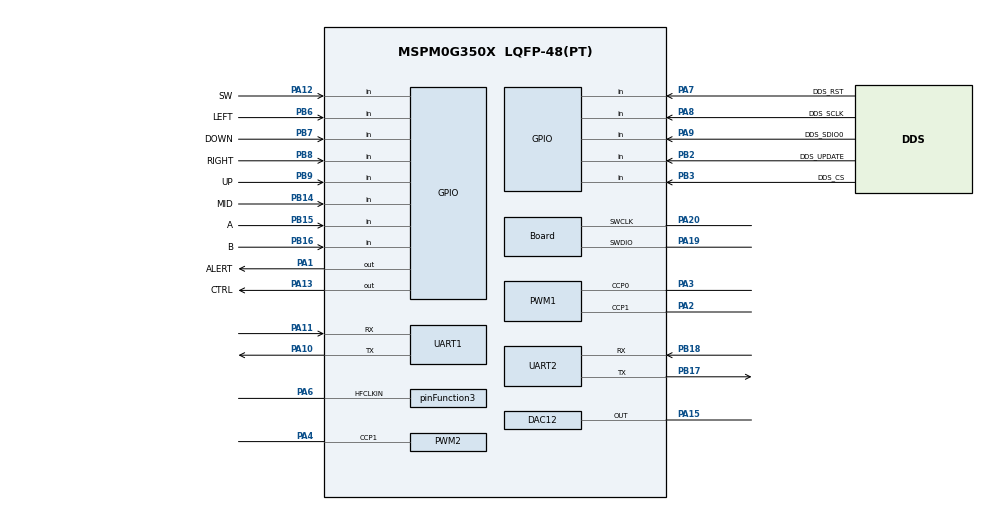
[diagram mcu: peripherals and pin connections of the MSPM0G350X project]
/**
 * @cliArgs --device "MSPM0G350X" --package "LQFP-48(PT)" --part "Default" --product "mspm0_sdk@2.10.00.04"
 * @versions {"tool":"1.19.0+3426"}
 */

/**
 * Import the modules used in this configuration.
 */
const ADC12         = scripting.addModule("/ti/driverlib/ADC12", {}, false);
const ADC121        = ADC12.addInstance();
const ADC122        = ADC12.addInstance();
const DAC12         = scripting.addModule("/ti/driverlib/DAC12");
const GPIO          = scripting.addModule("/ti/driverlib/GPIO", {}, false);
const GPIO1         = GPIO.addInstance();
const GPIO2         = GPIO.addInstance();
const GPIO3         = GPIO.addInstance();
const GPIO4         = GPIO.addInstance();
const GPIO5         = GPIO.addInstance();
const DMA           = scripting.addModule("/ti/driverlib/DMA");
const MATHACL       = scripting.addModule("/ti/driverlib/MATHACL");
const PWM           = scripting.addModule("/ti/driverlib/PWM", {}, false);
const PWM1          = PWM.addInstance();
const PWM2          = PWM.addInstance();
const SYSCTL        = scripting.addModule("/ti/driverlib/SYSCTL");
const SYSTICK       = scripting.addModule("/ti/driverlib/SYSTICK");
const TIMER         = scripting.addModule("/ti/driverlib/TIMER", {}, false);
const TIMER1        = TIMER.addInstance();
const UART          = scripting.addModule("/ti/driverlib/UART", {}, false);
const UART1         = UART.addInstance();
const UART2         = UART.addInstance();
const ProjectConfig = scripting.addModule("/ti/project_config/ProjectConfig");

/**
 * Write custom configuration values to the imported modules.
 */
const divider9       = system.clockTree["UDIV"];
divider9.divideValue = 2;

const dacClockGate    = system.clockTree["MFPCLKGATE"];
dacClockGate.enable   = true;

const multiplier2         = system.clockTree["PLL_QDIV"];
multiplier2.multiplyValue = 4;

const mux2       = system.clockTree["CANCLKMUX"];
mux2.inputSelect = "CANCLKMUX_PLLCLK1_OUT";

const mux8       = system.clockTree["HSCLKMUX"];
mux8.inputSelect = "HSCLKMUX_SYSPLL0";

const mux12       = system.clockTree["SYSPLLMUX"];
mux12.inputSelect = "zSYSPLLMUX_HFCLK";

const pinFunction3                         = system.clockTree["HFCLKEXT"];
pinFunction3.enable                        = true;
pinFunction3.inputFreq                     = 40;
pinFunction3.peripheral.$assign            = "SYSCTL";
pinFunction3.peripheral.hfclkInPin.$assign = "PA6";

ADC121.$name                             = "ADC0";
ADC121.repeatMode                        = true;
ADC121.configureDMA                      = true;
ADC121.enableFIFO                        = true;
ADC121.sampCnt                           = 6;
ADC121.enabledDMATriggers                = ["DL_ADC12_DMA_MEM11_RESULT_LOADED"];
ADC121.adcMem0trig                       = "DL_ADC12_TRIGGER_MODE_TRIGGER_NEXT";
ADC121.trigSrc                           = "DL_ADC12_TRIG_SRC_EVENT";
ADC121.subChanID                         = 15;
ADC121.sampClkSrc                        = "DL_ADC12_CLOCK_HFCLK";
ADC121.sampleTime0                       = "1 us";
ADC121.powerDownMode                     = "DL_ADC12_POWER_DOWN_MODE_MANUAL";
ADC121.sampleTime1                       = "1 us";
ADC121.enabledInterrupts                 = ["DL_ADC12_INTERRUPT_DMA_DONE"];
ADC121.peripheral.$assign                = "ADC0";
ADC121.peripheral.adcPin0.$assign        = "PA27";
ADC121.adcPin0Config.$name               = "ti_driverlib_gpio_GPIOPinGeneric0";
ADC121.adcPin0Config.hideOutputInversion = scripting.forceWrite(false);
ADC121.DMA_CHANNEL.$name                 = "DMA_CH0";
ADC121.DMA_CHANNEL.addressMode           = "f2b";
ADC121.DMA_CHANNEL.peripheral.$assign    = "DMA_CH0";

ADC122.$name                             = "ADC1";
ADC122.repeatMode                        = true;
ADC122.configureDMA                      = true;
ADC122.enableFIFO                        = true;
ADC122.sampCnt                           = 6;
ADC122.enabledDMATriggers                = ["DL_ADC12_DMA_MEM11_RESULT_LOADED"];
ADC122.adcMem0trig                       = "DL_ADC12_TRIGGER_MODE_TRIGGER_NEXT";
ADC122.adcMem0chansel                    = "DL_ADC12_INPUT_CHAN_1";
ADC122.trigSrc                           = "DL_ADC12_TRIG_SRC_EVENT";
/* ADC_TRIGGER_TIMER publishes its trigger event on channel 15. */
ADC122.subChanID                         = 15;
ADC122.sampClkSrc                        = "DL_ADC12_CLOCK_HFCLK";
ADC122.sampleTime0                       = "1 us";
ADC122.powerDownMode                     = "DL_ADC12_POWER_DOWN_MODE_MANUAL";
ADC122.enabledInterrupts                 = ["DL_ADC12_INTERRUPT_DMA_DONE"];
ADC122.peripheral.$assign                = "ADC1";
ADC122.peripheral.adcPin1.$assign        = "PA16";
ADC122.DMA_CHANNEL.$name                 = "DMA_CH1";
ADC122.DMA_CHANNEL.addressMode           = "f2b";
ADC122.DMA_CHANNEL.peripheral.$assign    = "DMA_CH1";

/*
 * PA15 is now reserved for the single hardware DAC.  ADC1/Q was moved to
 * PA16 (A1_1), so capture and demodulated waveform playback can run at the
 * same time without sharing a pin.
 */
DAC12.dacConfigureDMA                = true;
DAC12.dacFIFOEn                      = true;
DAC12.dacFIFOThresh                  = "TWO_QTRS_EMPTY";
DAC12.dacEnabledInterrupts           = ["DMA_DONE"];
DAC12.dacOutputPinEn                 = true;
DAC12.dacAmplifier                   = "ON";
DAC12.dacSampleTimerRate             = "1M";
DAC12.peripheral.$assign             = "DAC0";
DAC12.peripheral.OutPin.$assign      = "PA15";
DAC12.OutPinConfig.$name             = "ti_driverlib_gpio_GPIOPinGeneric12";
DAC12.DMA_CHANNEL.$name              = "DMA_CH2";
DAC12.DMA_CHANNEL.transferMode       = "FULL_CH_REPEAT_SINGLE";
DAC12.DMA_CHANNEL.addressMode        = "b2f";
DAC12.DMA_CHANNEL.srcLength          = "HALF_WORD";
DAC12.DMA_CHANNEL.dstLength          = "HALF_WORD";
DAC12.DMA_CHANNEL.peripheral.$assign = "DMA_CH2";

const Board                       = scripting.addModule("/ti/driverlib/Board", {}, false);
Board.peripheral.$assign          = "DEBUGSS";
Board.peripheral.swclkPin.$assign = "PA20";
Board.peripheral.swdioPin.$assign = "PA19";

GPIO1.$name                          = "GPIO_DDS";
GPIO1.associatedPins.create(5);
GPIO1.associatedPins[0].$name        = "DDS_SCLK";
GPIO1.associatedPins[0].direction    = "INPUT";
GPIO1.associatedPins[0].assignedPort = "PORTA";
GPIO1.associatedPins[0].assignedPin  = "8";
GPIO1.associatedPins[0].pin.$assign  = "PA8";
GPIO1.associatedPins[1].$name        = "DDS_SDIO0";
GPIO1.associatedPins[1].direction    = "INPUT";
GPIO1.associatedPins[1].assignedPort = "PORTA";
GPIO1.associatedPins[1].assignedPin  = "9";
GPIO1.associatedPins[1].pin.$assign  = "PA9";
GPIO1.associatedPins[2].$name        = "DDS_CS";
GPIO1.associatedPins[2].direction    = "INPUT";
GPIO1.associatedPins[2].assignedPort = "PORTB";
GPIO1.associatedPins[2].assignedPin  = "3";
GPIO1.associatedPins[2].pin.$assign  = "PB3";
GPIO1.associatedPins[3].$name        = "DDS_UPDATE";
GPIO1.associatedPins[3].direction    = "INPUT";
GPIO1.associatedPins[3].assignedPort = "PORTB";
GPIO1.associatedPins[3].assignedPin  = "2";
GPIO1.associatedPins[3].pin.$assign  = "PB2";
GPIO1.associatedPins[4].$name        = "DDS_RST";
GPIO1.associatedPins[4].direction    = "INPUT";
GPIO1.associatedPins[4].assignedPort = "PORTA";
GPIO1.associatedPins[4].assignedPin  = "7";
GPIO1.associatedPins[4].pin.$assign  = "PA7";

GPIO2.$name                              = "GPIO_BTN";
GPIO2.port                               = "PORTB";
GPIO2.associatedPins.create(5);
GPIO2.associatedPins[0].$name            = "LEFT";
GPIO2.associatedPins[0].direction        = "INPUT";
GPIO2.associatedPins[0].assignedPin      = "6";
GPIO2.associatedPins[0].internalResistor = "PULL_UP";
GPIO2.associatedPins[0].pin.$assign      = "PB6";
GPIO2.associatedPins[1].$name            = "DOWN";
GPIO2.associatedPins[1].direction        = "INPUT";
GPIO2.associatedPins[1].assignedPin      = "7";
GPIO2.associatedPins[1].internalResistor = "PULL_UP";
GPIO2.associatedPins[1].pin.$assign      = "PB7";
GPIO2.associatedPins[2].$name            = "RIGHT";
GPIO2.associatedPins[2].direction        = "INPUT";
GPIO2.associatedPins[2].assignedPin      = "8";
GPIO2.associatedPins[2].internalResistor = "PULL_UP";
GPIO2.associatedPins[2].pin.$assign      = "PB8";
GPIO2.associatedPins[3].$name            = "UP";
GPIO2.associatedPins[3].direction        = "INPUT";
GPIO2.associatedPins[3].assignedPin      = "9";
GPIO2.associatedPins[3].internalResistor = "PULL_UP";
GPIO2.associatedPins[3].pin.$assign      = "PB9";
GPIO2.associatedPins[4].$name            = "MID";
GPIO2.associatedPins[4].direction        = "INPUT";
GPIO2.associatedPins[4].assignedPin      = "14";
GPIO2.associatedPins[4].internalResistor = "PULL_UP";
GPIO2.associatedPins[4].pin.$assign      = "PB14";

GPIO3.$name                              = "GPIO_ENC";
GPIO3.associatedPins.create(3);
GPIO3.associatedPins[0].$name            = "A";
GPIO3.associatedPins[0].direction        = "INPUT";
GPIO3.associatedPins[0].assignedPort     = "PORTB";
GPIO3.associatedPins[0].assignedPin      = "15";
GPIO3.associatedPins[0].interruptEn      = true;
GPIO3.associatedPins[0].polarity         = "RISE";
GPIO3.associatedPins[0].pin.$assign      = "PB15";
GPIO3.associatedPins[1].$name            = "B";
GPIO3.associatedPins[1].assignedPort     = "PORTB";
GPIO3.associatedPins[1].assignedPin      = "16";
GPIO3.associatedPins[1].direction        = "INPUT";
GPIO3.associatedPins[1].pin.$assign      = "PB16";
GPIO3.associatedPins[2].$name            = "SW";
GPIO3.associatedPins[2].assignedPort     = "PORTA";
GPIO3.associatedPins[2].assignedPin      = "12";
GPIO3.associatedPins[2].direction        = "INPUT";
GPIO3.associatedPins[2].internalResistor = "PULL_UP";
GPIO3.associatedPins[2].pin.$assign      = "PA12";

/*
 * F-problem output-path relay.
 * PA13 low: relay released, NC -> COM, source input passes through.
 * PA13 high: relay energized, NO -> COM, DDS amplifier drives the output.
 */
GPIO4.$name                          = "GPIO_RELAY";
GPIO4.associatedPins.create(1);
GPIO4.associatedPins[0].$name        = "CTRL";
GPIO4.associatedPins[0].assignedPort = "PORTA";
GPIO4.associatedPins[0].assignedPin  = "13";
GPIO4.associatedPins[0].pin.$assign  = "PA13";

/*
 * Dedicated external sound/light output.
 * PA1 high: S8050 on, external active buzzer and LED both on.
 * PA1 low:  S8050 off, both loads off. This pin is not shared with RGB/DDS.
 */
GPIO5.$name                          = "GPIO_SOUND_LIGHT";
GPIO5.associatedPins.create(1);
GPIO5.associatedPins[0].$name        = "ALERT";
GPIO5.associatedPins[0].assignedPort = "PORTA";
GPIO5.associatedPins[0].assignedPin  = "1";
GPIO5.associatedPins[0].pin.$assign  = "PA1";

PWM1.$name                              = "PWM_LED_RG";
PWM1.timerCount                         = 1023;
PWM1.timerStartTimer                    = true;
PWM1.pwmMode                            = "EDGE_ALIGN_UP";
PWM1.peripheral.$assign                 = "TIMG7";
PWM1.peripheral.ccp0Pin.$assign         = "PA3";
PWM1.peripheral.ccp1Pin.$assign         = "PA2";
PWM1.PWM_CHANNEL_0.$name                = "ti_driverlib_pwm_PWMTimerCC0";
PWM1.PWM_CHANNEL_0.dutyCycle            = 0;
PWM1.PWM_CHANNEL_1.$name                = "ti_driverlib_pwm_PWMTimerCC1";
PWM1.PWM_CHANNEL_1.dutyCycle            = 0;
PWM1.ccp0PinConfig.$name                = "ti_driverlib_gpio_GPIOPinGeneric7";
PWM1.ccp0PinConfig.direction            = scripting.forceWrite("OUTPUT");
PWM1.ccp0PinConfig.hideOutputInversion  = scripting.forceWrite(false);
PWM1.ccp0PinConfig.onlyInternalResistor = scripting.forceWrite(false);
PWM1.ccp0PinConfig.passedPeripheralType = scripting.forceWrite("Digital");
PWM1.ccp1PinConfig.$name                = "ti_driverlib_gpio_GPIOPinGeneric8";
PWM1.ccp1PinConfig.direction            = scripting.forceWrite("OUTPUT");
PWM1.ccp1PinConfig.hideOutputInversion  = scripting.forceWrite(false);
PWM1.ccp1PinConfig.onlyInternalResistor = scripting.forceWrite(false);
PWM1.ccp1PinConfig.passedPeripheralType = scripting.forceWrite("Digital");

PWM2.$name                              = "PWM_LED_B";
PWM2.timerCount                         = 1023;
PWM2.timerStartTimer                    = true;
PWM2.pwmMode                            = "EDGE_ALIGN_UP";
PWM2.ccIndex                            = [1];
PWM2.peripheral.$assign                 = "TIMG8";
PWM2.peripheral.ccp1Pin.$assign         = "PA4";
PWM2.ccp1PinConfig.$name                = "ti_driverlib_gpio_GPIOPinGeneric10";
PWM2.ccp1PinConfig.direction            = scripting.forceWrite("OUTPUT");
PWM2.ccp1PinConfig.hideOutputInversion  = scripting.forceWrite(false);
PWM2.ccp1PinConfig.onlyInternalResistor = scripting.forceWrite(false);
PWM2.ccp1PinConfig.passedPeripheralType = scripting.forceWrite("Digital");
PWM2.PWM_CHANNEL_1.$name                = "ti_driverlib_pwm_PWMTimerCC2";
PWM2.PWM_CHANNEL_1.dutyCycle            = 0;

SYSCTL.clockTreeEn = true;
SYSCTL.MFPCLKEn    = true;

SYSTICK.periodEnable    = true;
SYSTICK.period          = 80000;
SYSTICK.interruptEnable = true;
SYSTICK.systickEnable   = true;

TIMER1.$name                       = "ADC_TRIGGER_TIMER";
TIMER1.timerMode                   = "PERIODIC";
TIMER1.timerPeriod                 = "10us";
TIMER1.event1PublisherChannel      = 15;
TIMER1.event1ControllerInterruptEn = ["ZERO_EVENT"];
TIMER1.peripheral.$assign          = "TIMG0";

UART1.$name                    = "UART_0";
UART1.targetBaudRate           = 115200;
UART1.peripheral.$assign       = "UART0";
UART1.peripheral.rxPin.$assign = "PA11";
UART1.peripheral.txPin.$assign = "PA10";
UART1.txPinConfig.$name        = "ti_driverlib_gpio_GPIOPinGeneric3";
UART1.rxPinConfig.$name        = "ti_driverlib_gpio_GPIOPinGeneric4";

UART2.targetBaudRate                   = 115200;
UART2.$name                            = "UART_2";
UART2.peripheral.$assign               = "UART2";
UART2.peripheral.rxPin.$assign         = "PB18";
UART2.peripheral.txPin.$assign         = "PB17";
UART2.txPinConfig.direction            = scripting.forceWrite("OUTPUT");
UART2.txPinConfig.hideOutputInversion  = scripting.forceWrite(false);
UART2.txPinConfig.onlyInternalResistor = scripting.forceWrite(false);
UART2.txPinConfig.passedPeripheralType = scripting.forceWrite("Digital");
UART2.txPinConfig.$name                = "ti_driverlib_gpio_GPIOPinGeneric5";
UART2.rxPinConfig.hideOutputInversion  = scripting.forceWrite(false);
UART2.rxPinConfig.onlyInternalResistor = scripting.forceWrite(false);
UART2.rxPinConfig.passedPeripheralType = scripting.forceWrite("Digital");
UART2.rxPinConfig.$name                = "ti_driverlib_gpio_GPIOPinGeneric6";

ProjectConfig.deviceSpin = "MSPM0G3507";
ProjectConfig.genLibIQ = true;
ProjectConfig.genLibIQVersion = "MATHACL";
scripting.suppress("Migrating requires going through the Switch Board or Device menu in the Device View section\\.", ProjectConfig, "deviceSpin");
